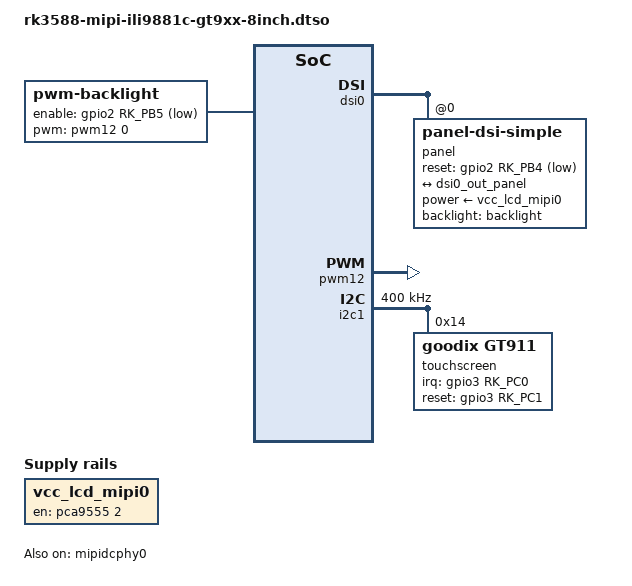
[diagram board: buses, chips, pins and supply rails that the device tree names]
/dts-v1/;
/plugin/;

#include <dt-bindings/gpio/gpio.h>
#include <dt-bindings/interrupt-controller/irq.h>
#include <dt-bindings/pinctrl/rockchip.h>
#include <dt-bindings/soc/rockchip,vop2.h>
#include <dt-bindings/display/drm_mipi_dsi.h>

/ {
	compatible = "firefly,icore-3588q";
};

&{/} {
	vcc_lcd_mipi0: regulator-vcc-lcd-mipi0 {
		compatible = "regulator-fixed";
		regulator-name = "vcc_lcd_mipi0";
		enable-active-high;
		gpio = <&pca9555 2 GPIO_ACTIVE_HIGH>; //PCA_IO0_2
	};

	backlight: backlight {
		status = "okay";
		compatible = "pwm-backlight";
		enable-gpios = <&gpio2 RK_PB5 GPIO_ACTIVE_LOW>;
		pwms = <&pwm12 0 50000 1>;
		brightness-levels = <
			 60  60  60  61  61  61  62  62
			 62  63  63  63  64  64  64  65
			 65  65  66  66  66  67  67  67
			 68  68  68  69  69  69  70  70
			 70  71  71  71  72  72  72  73
			 73  73  74  74  74  75  75  75
			 76  76  76  77  77  77  78  78
			 78  79  79  79  80  80  80  81
			 81  81  82  82  82  83  83  83
			 84  84  84  85  85  85  86  86
			 86  87  87  87  88  88  88  89
			 89  89  90  91  92  93  94  95
			 96  97  98  99 100 101 102 103
			104 105 106 107 108 109 110 111
			112 113 114 115 116 117 118 119
			120 121 122 123 124 125 126 127
			128 129 130 131 132 133 134 135
			136 137 138 139 140 141 142 143
			144 145 146 147 148 149 150 151
			152 153 154 155 156 157 158 159
			160 161 162 163 164 165 166 167
			168 169 170 171 172 173 174 175
			176 177 178 179 180 181 182 183
			184 185 186 187 188 189 190 191
			192 193 194 195 196 197 198 199
			200 201 202 203 204 205 206 207
			208 209 210 211 212 213 214 215
			216 217 218 219 220 221 222 223
			224 225 226 227 228 229 230 231
			232 233 234 235 236 237 238 239
			240 241 242 243 244 245 246 247
			248 249 250 251 252 253 254 255
		>;
		default-brightness-level = <150>;
	};
};

&dsi0 {
	#address-cells = <1>;
	#size-cells = <0>;
	status = "okay";
	rockchip,lane-rate = <540>;

	panel@0 {
		status = "okay";
		compatible = "panel-dsi-simple";
		reg = <0>;
		backlight = <&backlight>;

		power-supply = <&vcc_lcd_mipi0>;
		reset-gpios = <&gpio2 RK_PB4 GPIO_ACTIVE_LOW>;

		// enable-delay-ms = <50>;
		prepare-delay-ms = <200>;
		reset-delay-ms = <50>;
		init-delay-ms = <55>;
		unprepare-delay-ms = <50>;
		// disable-delay-ms = <20>;
		width-mm = <120>;
		height-mm = <170>;
		dsi,flags = <(MIPI_DSI_MODE_VIDEO | MIPI_DSI_MODE_VIDEO_BURST | MIPI_DSI_MODE_LPM | MIPI_DSI_MODE_NO_EOT_PACKET)>;
		dsi,format = <MIPI_DSI_FMT_RGB888>;
		dsi,lanes  = <4>;

		panel-init-sequence = [
			39 00 04 FF 98 81 03
			15 00 02 01 00
			15 00 02 02 00
			15 00 02 03 57
			15 00 02 04 D3
			15 00 02 05 00
			15 00 02 06 11
			15 00 02 07 08
			15 00 02 08 00
			15 00 02 09 00
			15 00 02 0A 3F
			15 00 02 0B 00
			15 00 02 0C 00
			15 00 02 0D 00
			15 00 02 0E 00
			15 00 02 0F 3F
			15 00 02 10 3F
			15 00 02 11 00
			15 00 02 12 00
			15 00 02 13 00
			15 00 02 14 00
			15 00 02 15 00
			15 00 02 16 00
			15 00 02 17 00
			15 00 02 18 00
			15 00 02 19 00
			15 00 02 1A 00
			15 00 02 1B 00
			15 00 02 1C 00
			15 00 02 1D 00
			15 00 02 1E 40
			15 00 02 1F 80
			15 00 02 20 06
			15 00 02 21 01
			15 00 02 22 00
			15 00 02 23 00
			15 00 02 24 00
			15 00 02 25 00
			15 00 02 26 00
			15 00 02 27 00
			15 00 02 28 33
			15 00 02 29 33
			15 00 02 2A 00
			15 00 02 2B 00
			15 00 02 2C 00
			15 00 02 2D 00
			15 00 02 2E 00
			15 00 02 2F 00
			15 00 02 30 00
			15 00 02 31 00
			15 00 02 32 00
			15 00 02 33 00
			15 00 02 34 00
			15 00 02 35 00
			15 00 02 36 00
			15 00 02 37 00
			15 00 02 38 78
			15 00 02 39 00
			15 00 02 3A 00
			15 00 02 3B 00
			15 00 02 3C 00
			15 00 02 3D 00
			15 00 02 3E 00
			15 00 02 3F 00
			15 00 02 40 00
			15 00 02 41 00
			15 00 02 42 00
			15 00 02 43 00
			15 00 02 44 00
			15 00 02 50 00
			15 00 02 51 23
			15 00 02 52 45
			15 00 02 53 67
			15 00 02 54 89
			15 00 02 55 AB
			15 00 02 56 01
			15 00 02 57 23
			15 00 02 58 45
			15 00 02 59 67
			15 00 02 5A 89
			15 00 02 5B AB
			15 00 02 5C CD
			15 00 02 5D EF
			15 00 02 5E 00
			15 00 02 5F 0D
			15 00 02 60 0D
			15 00 02 61 0C
			15 00 02 62 0C
			15 00 02 63 0F
			15 00 02 64 0F
			15 00 02 65 0E
			15 00 02 66 0E
			15 00 02 67 08
			15 00 02 68 02
			15 00 02 69 02
			15 00 02 6A 02
			15 00 02 6B 02
			15 00 02 6C 02
			15 00 02 6D 02
			15 00 02 6E 02
			15 00 02 6F 02
			15 00 02 70 14
			15 00 02 71 15
			15 00 02 72 06
			15 00 02 73 02
			15 00 02 74 02
			15 00 02 75 0D
			15 00 02 76 0D
			15 00 02 77 0C
			15 00 02 78 0C
			15 00 02 79 0F
			15 00 02 7A 0F
			15 00 02 7B 0E
			15 00 02 7C 0E
			15 00 02 7D 08
			15 00 02 7E 02
			15 00 02 7F 02
			15 00 02 80 02
			15 00 02 81 02
			15 00 02 82 02
			15 00 02 83 02
			15 00 02 84 02
			15 00 02 85 02
			15 00 02 86 14
			15 00 02 87 15
			15 00 02 88 06
			15 00 02 89 02
			15 00 02 8A 02
			39 00 04 FF 98 81 04
			15 00 02 6E 3B
			15 00 02 6F 57
			15 00 02 3A 24
			15 00 02 8D 1F
			15 00 02 87 0A
			15 00 02 B2 D1
			15 00 02 88 0B
			15 00 02 38 01
			15 00 02 39 00
			15 00 02 B5 07
			15 00 02 31 75
			15 00 02 3B 98
			39 00 04 FF 98 81 01
			15 00 02 22 0A
			15 00 02 31 09
			15 00 02 35 07
			15 00 02 53 87
			15 00 02 55 84
			15 00 02 50 86
			15 00 02 51 82
			15 00 02 60 10
			15 00 02 62 00
			15 00 02 A0 00
			15 00 02 A1 12
			15 00 02 A2 1F
			15 00 02 A3 12
			15 00 02 A4 16
			15 00 02 A5 29
			15 00 02 A6 1E
			15 00 02 A7 1F
			15 00 02 A8 7E
			15 00 02 A9 1B
			15 00 02 AA 28
			15 00 02 AB 6D
			15 00 02 AC 19
			15 00 02 AD 18
			15 00 02 AE 4C
			15 00 02 AF 1E
			15 00 02 B0 23
			15 00 02 B1 52
			15 00 02 B2 6D
			15 00 02 B3 3F
			15 00 02 C0 00
			15 00 02 C1 12
			15 00 02 C2 20
			15 00 02 C3 10
			15 00 02 C4 13
			15 00 02 C5 27
			15 00 02 C6 1B
			15 00 02 C7 1D
			15 00 02 C8 75
			15 00 02 C9 1F
			15 00 02 CA 28
			15 00 02 CB 68
			15 00 02 CC 1A
			15 00 02 CD 18
			15 00 02 CE 4D
			15 00 02 CF 25
			15 00 02 D0 2E
			15 00 02 D1 53
			15 00 02 D2 60
			15 00 02 D3 3F
			39 00 04 FF 98 81 00
			15 00 02 35 00
			15 78 02 11 00
			15 14 02 29 00
		];

		panel-exit-sequence = [
			05 00 01 28
			05 00 01 10
		];

		display-timings {
			native-mode = <&dsi0_timing0>;
			dsi0_timing0: timing0 {
				clock-frequency = <62100000>;
				hactive = <800>;
				vactive = <1280>;
				hsync-len = <20>;
				hback-porch = <50>;
				hfront-porch = <50>;
				vsync-len = <2>;
				vback-porch = <10>;
				vfront-porch = <8>;
				hsync-active = <0>;
				vsync-active = <0>;
				de-active = <0>;
				pixelclk-active = <0>;
			};
		};

		port {
			mipi_panel_in: endpoint {
				remote-endpoint = <&dsi0_out_panel>;
			};
		};
	};
};

&dsi0_in {
	dsi0_in_vp3: endpoint {
		remote-endpoint = <&vp3_out_dsi0>;
	};
};

&dsi0_out {
	dsi0_out_panel: endpoint {
		remote-endpoint = <&mipi_panel_in>;
	};
};

&mipidcphy0 {
	status = "okay";
};

&pwm12 {
	pinctrl-0 = <&pwm12m1_pins>;
	status = "okay";
};

&vp3 {
	#address-cells = <1>;
	#size-cells = <0>;

	vp3_out_dsi0: endpoint@ROCKCHIP_VOP2_EP_MIPI0 {
		reg = <ROCKCHIP_VOP2_EP_MIPI0>;
		remote-endpoint = <&dsi0_in_vp3>;
	};
};

&i2c1{
	status = "okay";
	pinctrl-names = "default";
	pinctrl-0 = <&i2c1m2_xfer>;
	clock-frequency = <400000>;

	touchscreen@14 {
		compatible = "goodix,gt911";
		reg = <0x14>;
		interrupt-parent = <&gpio3>;
		interrupts = <RK_PC0 IRQ_TYPE_LEVEL_LOW>;
		irq-gpios = <&gpio3 RK_PC0 GPIO_ACTIVE_HIGH>;
		pinctrl-names = "default";
		pinctrl-0 = <&touch_int0>;
		reset-gpios = <&gpio3 RK_PC1 GPIO_ACTIVE_HIGH>;
		touchscreen-size-x = <800>;
		touchscreen-size-y = <1280>;
	};
};

&pinctrl {
	touch {
		touch_int0: touch-int0 {
			rockchip,pins = <3 RK_PC0 RK_FUNC_GPIO &pcfg_pull_up>;
		};
	};
};

&hdmi0 {
	status = "disabled";
};
